AUTOSAR XML (schema 4-2-2)
standard types defined: uint8, uint16, sint8
package /AUTOSAR/Compositions
  composition sw component type BottomComposition
    component CptObs_APrototype: type=CptObs_A
    component CptCtrl_APrototype: type=CptCtrl_A
    connect CptCtrl_APrototype.PpExplict -> CptObs_APrototype.RpExplicit
  composition sw component type TopComposition
    component BottomComposition: type=BottomComposition
package /AUTOSAR/SwcImplementations
  swc implementation swcImplementation_CptObs_A: behavior=IbObs_A
  swc implementation swcImplementation_CptCtrl_A: behavior=IbCtrl_A
package /AUTOSAR/System
  system system_0
    system mapping SystemMapping_0: sender-receiver-to-signal-group-mapping{data-element=BottomComposition.CptCtrl_APrototype.rootSwCompositionPrototype_0.PpExplict.dataElementStruct, signal-group=SignalGroupStructA36_MsgStructA, type-mapping=sender-rec-record-type-mapping=record-element-mappings=[{implementation-record-element=Crc_Uint8, system-signal=SignalCrc8_MsgStructA}, {implementation-record-element=Data_Uint16, system-signal=SignalData16_MsgStructA}, {implementation-record-element=Counter_Uint8, system-signal=SignalCounter4_MsgStructA}, {implementation-record-element=Data_Uint8, system-signal=SignalData8_MsgStructA}]}
      sw-impl-mappings:
        swc to impl mapping CptSenderPrototypeImplMapping: component-implementation=swcImplementation_CptCtrl_A, component=rootSwCompositionPrototype_0.BottomComposition.CptCtrl_APrototype.CptCtrl_APrototype
        swc to impl mapping CptReceiverPrototypeImplMapping: component-implementation=swcImplementation_CptObs_A, component=rootSwCompositionPrototype_0.BottomComposition.CptObs_APrototype.CptObs_APrototype
      sw-mappings:
        swc to ecu mapping ECUA_SwcToEcuMapping: ecu-instance=ECUA
          component:
            rootSwCompositionPrototype_0.BottomComposition.CptCtrl_APrototype.CptCtrl_APrototype
            rootSwCompositionPrototype_0.BottomComposition.CptObs_APrototype.CptObs_APrototype
    root-software-compositions:
      root sw composition prototype rootSwCompositionPrototype_0: software-composition=TopComposition
package /AUTOSAR/Components
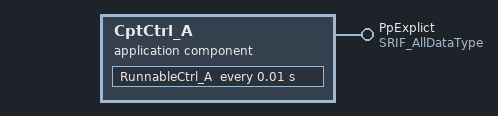
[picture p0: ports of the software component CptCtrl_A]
  application sw component type CptCtrl_A
    provide port PpExplict: provided-interface=SRIF_AllDataType
    behavior IbCtrl_A
      timing event timingEvent_10: start-on-event=RunnableCtrl_A, period=0.01
      runnable RunnableCtrl_A: symbol=AppRunnableCtrl
        data-send-points:
          access DataSendPointsPrimitive: accessed-variable=PpExplict.dataElementPrimitive
          access dataSendPointsArray: accessed-variable=PpExplict.dataElementArray
          access dataSendPointsStruct: accessed-variable=PpExplict.dataElementStruct
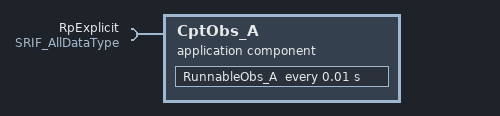
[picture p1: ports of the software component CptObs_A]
  application sw component type CptObs_A
    require port RpExplicit: required-interface=SRIF_AllDataType
      required-com-specs:
        data-element=dataElementPrimitive, external-replacement=dataElementPrimitive, init-value=0
        data-element=dataElementStruct, init-value=fields=[0, 1, 2]
        data-element=dataElementArray, init-value=[0]
    behavior IbObs_A
      timing event timingEvent_10: start-on-event=RunnableObs_A, period=0.01
      runnable RunnableObs_A: symbol=AppRunnable_Obs
        data-receive-point-by-arguments:
          access DataReceiveByArgPrimitive: accessed-variable=RpExplicit.dataElementPrimitive
          access DataReceiveByArgArray: accessed-variable=RpExplicit.dataElementArray
          access DataReceiveByArgStruct: accessed-variable=RpExplicit.dataElementStruct
package /AUTOSAR/Interfaces
  sender receiver interface SRIF_AllDataType
    data dataElementPrimitive: type=PrimitiveUint16
    data dataElementArray: type=ArrayUint8
    data dataElementStruct: type=StructA
package /AUTOSAR/DataTypes
  impl type ArrayUint8: category=ARRAY
    element subElement: category=VALUE, array-size=10, base-type=uint8
  impl type StructA: category=STRUCTURE
    4 x element:
      Crc_Uint8: category=VALUE, base-type=uint8
      Data_Uint16: category=VALUE, base-type=uint16
      Counter_Uint8: category=VALUE, base-type=uint8
      Data_Uint8: base-type=uint8
  impl type PrimitiveUint16: category=VALUE, base-type=uint16
package /SystemInfo/ISignals
  i signal group SignalGroupStructA36_MsgStructA: i-signal=[SignalData8_MsgStructA, SignalCounter4_MsgStructA, SignalCrc8_MsgStructA, SignalData16_MsgStructA], system-signal-group=SignalGroupStructA36_MsgStructA
package /SystemInfo/EcuInstances
  ecu instance ECUA: com-configuration-gw-time-base=0.005, com-configuration-rx-time-base=0.005, com-configuration-tx-time-base=0.005, sleep-mode-supported=false, wake-up-over-bus-supported=false
    can communication controller CanChannel_0_ECUA: wake-up-by-controller-supported=false, can-controller-attributes=can-controller-configuration={sync-jump-width=0, time-seg-1=20, time-seg-2=10}
    can communication connector CanChannel_0_ECUA_conn: comm-controller=CanChannel_0_ECUA
package /SystemInfo/CanClusters
  can cluster CanCluster_0: protocol-name=CAN
    can physical channel CanChannel_0: comm-connectors=CanChannel_0_ECUA_conn
      frame MsgStructA: id 0x302, from ECUA, frame-length=8, can-addressing-mode=STANDARD
        pdu MsgStructA: length=8, transmission-mode-conditions=[SignalData8_MsgStructA, SignalData16_MsgStructA, SignalCounter4_MsgStructA, SignalCrc8_MsgStructA], transmission-mode-true-timing=cyclic-timing=time-period=0.1
          signal SignalData8_MsgStructA: start 32, 8 bit, little-endian, base-type=sint8, update-indication-bit-position=-1
          signal SignalCounter4_MsgStructA: start 12, 4 bit, big-endian, base-type=uint8, update-indication-bit-position=-1
          mapping SignalGroupStructA36_MsgStructA: i-signal-group=SignalGroupStructA36_MsgStructA, update-indication-bit-position=-1
          signal SignalData16_MsgStructA: start 24, 16 bit, big-endian, base-type=uint16, update-indication-bit-position=-1
          signal SignalCrc8_MsgStructA: start 0, 8 bit, big-endian, base-type=uint8, update-indication-bit-position=-1
